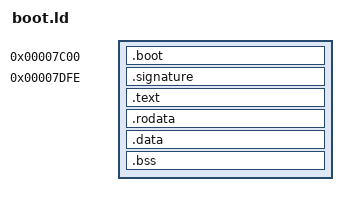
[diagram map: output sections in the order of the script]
OUTPUT_FORMAT(binary)
ENTRY(_start)

SECTIONS
{
	. = 0x7C00;
	_BOOT_START = .;

	.boot ALIGN(0x10) : {
		*(.boot*)
	}

	. = 0x7DFE;
	.signature : {
		SHORT(0xAA55);
	}

	.text ALIGN(0x10) : {
		_TEXT_START = .;
		*(.text*)
		_TEXT_END = .;
	}

	.rodata ALIGN(0x10) : {
		_RODATA_START = .;
		*(.rodata*)
		_RODATA_END = .;
	}

	.data ALIGN(0x10) : {
		_DATA_START = .;
		*(.data*)
		_DATA_END = .;
	}

	.bss ALIGN(0x10) : {
		_BSS_START = .;
		*(.bss*)
		_BSS_END = .;
	}

	/DISCARD/ : {
		*(.comment*)
	}

	_BOOT_END = .;
}

_IMAGE_SIZE = _BOOT_END - _BOOT_START;

_LARGE_DISK = _IMAGE_SIZE >= (2880 * 512);
_SECTORS_PER_HEAD = _IMAGE_SIZE ? 32: 18;
_HEADS_PER_CYLINDER = _IMAGE_SIZE ? 64: 2;
_SECTORS_PER_CYLINDER = _SECTORS_PER_HEAD * _HEADS_PER_CYLINDER;

_IMAGE_SECTORS = (_IMAGE_SIZE + 511) / 512;
_PARTITION_CHS_CYLINDER = _IMAGE_SECTORS / _SECTORS_PER_CYLINDER;
_PARTITION_BLOCKS = (_PARTITION_CHS_CYLINDER + 1) * _SECTORS_PER_CYLINDER;
_PARTITION_CHS_HEAD = _HEADS_PER_CYLINDER - 1;
_PARTITION_CHS_SECTOR = _SECTORS_PER_HEAD;

_PARTITION_CHS_CYLINDER_BYTE = _PARTITION_CHS_CYLINDER & 0xFF;
_PARTITION_CHS_SECTOR_BYTE = _PARTITION_CHS_SECTOR & 0xFF |
    ((_PARTITION_CHS_CYLINDER - _PARTITION_CHS_CYLINDER_BYTE) >> 2);

